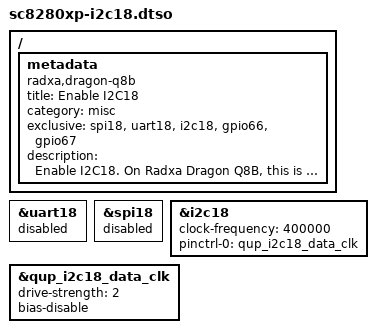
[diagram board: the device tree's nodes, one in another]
// SPDX-License-Identifier: BSD-3-Clause
/*
 * Copyright (c) 2026 Radxa Computer (Shenzhen) Co., Ltd.
 */

/dts-v1/;
/plugin/;

/ {
	metadata {
		title = "Enable I2C18";
		compatible = "radxa,dragon-q8b";
		category = "misc";
		exclusive = "spi18", "uart18", "i2c18", "gpio66", "gpio67";
		description = "Enable I2C18.
On Radxa Dragon Q8B, this is pin 15(scl), 13(sda).";
	};
};

&uart18 {
	status = "disabled";
};

&spi18 {
	status = "disabled";
};

&i2c18 {
	clock-frequency = <400000>;

	pinctrl-0 = <&qup_i2c18_data_clk>;
	pinctrl-names = "default";

	status = "okay";
};

&qup_i2c18_data_clk {
	drive-strength = <2>;
	bias-disable;
};
